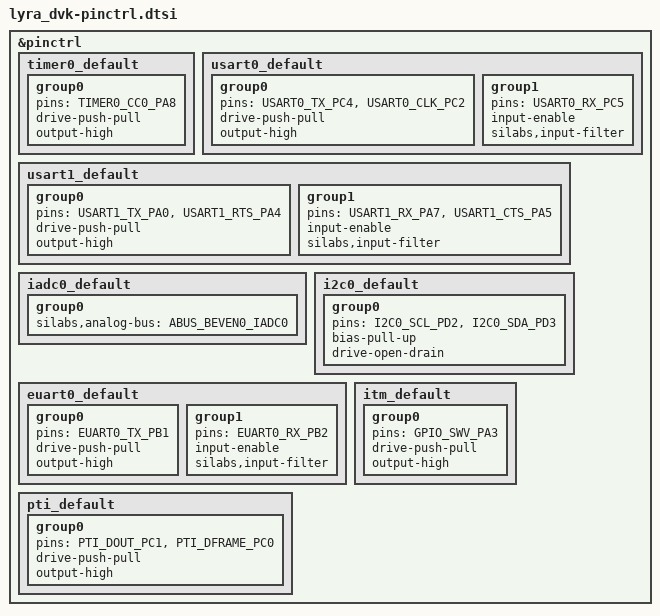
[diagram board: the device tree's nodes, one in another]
/*
 * Copyright The Zephyr Project Contributors
 * Copyright (c) 2026 Ezurio LLC
 *
 * SPDX-License-Identifier: Apache-2.0
 */

#include <dt-bindings/pinctrl/silabs/xg22-pinctrl.h>

&pinctrl {
	timer0_default: timer0_default {
		group0 {
			pins = <TIMER0_CC0_PA8>;
			drive-push-pull;
			output-high;
		};
	};

	usart0_default: usart0_default {
		group0 {
			pins = <USART0_TX_PC4>, <USART0_CLK_PC2>;
			drive-push-pull;
			output-high;
		};

		group1 {
			pins = <USART0_RX_PC5>;
			input-enable;
			silabs,input-filter;
		};
	};

	usart1_default: usart1_default {
		group0 {
			pins = <USART1_TX_PA0>, <USART1_RTS_PA4>;
			drive-push-pull;
			output-high;
		};

		group1 {
			pins = <USART1_RX_PA7>, <USART1_CTS_PA5>;
			input-enable;
			silabs,input-filter;
		};
	};

	iadc0_default: iadc0_default {
		group0 {
			silabs,analog-bus = <ABUS_BEVEN0_IADC0>;
		};
	};

	i2c0_default: i2c0_default {
		group0 {
			pins = <I2C0_SCL_PD2>, <I2C0_SDA_PD3>;
			bias-pull-up;
			drive-open-drain;
		};
	};

	euart0_default: euart0_default {
		group0 {
			pins = <EUART0_TX_PB1>;
			drive-push-pull;
			output-high;
		};

		group1 {
			pins = <EUART0_RX_PB2>;
			input-enable;
			silabs,input-filter;
		};
	};

	itm_default: itm_default {
		group0 {
			pins = <GPIO_SWV_PA3>;
			drive-push-pull;
			output-high;
		};
	};

	pti_default: pti_default {
		group0 {
			pins = <PTI_DOUT_PC1>, <PTI_DFRAME_PC0>;
			drive-push-pull;
			output-high;
		};
	};
};
